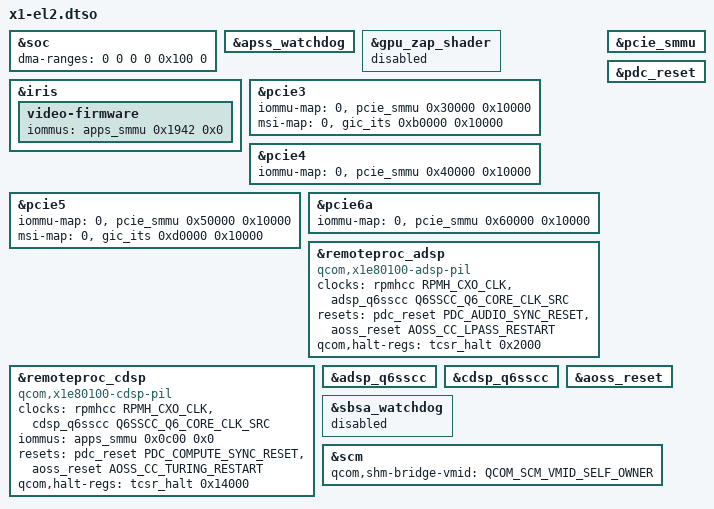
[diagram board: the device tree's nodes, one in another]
// SPDX-License-Identifier: BSD-3-Clause
#include <dt-bindings/clock/qcom,rpmh.h>
#include <dt-bindings/clock/qcom,x1e80100-q6sscc.h>
#include <dt-bindings/firmware/qcom,scm.h>
#include <dt-bindings/reset/qcom,sdm845-aoss.h>
#include <dt-bindings/reset/qcom,sdm845-pdc.h>

/*
 * x1 specific modifications required to boot in EL2.
 */

/dts-v1/;
/plugin/;



&soc {
	#address-cells = <2>;
	#size-cells = <2>;
	dma-ranges = <0 0 0 0 0x100 0>;
	ranges = <0 0 0 0 0x100 0>;
};

&apss_watchdog {
	status = "okay";
};

/* We can't and don't need to use zap shader in EL2 as linux can zap the gpu on it's own. */
&gpu_zap_shader {
	status = "disabled";
};

&iris {
	/* Use generic firmware in EL2 and enable it by default */
//	status = "okay";
//	firmware-name = "qcom/vpu/vpu30_p4.mbn";

	video-firmware {
		iommus = <&apps_smmu 0x1942 0x0>;
	};
};

/*
 * When running under Gunyah, this IOMMU is controlled by the firmware,
 * however when we take ownership of it in EL2, we need to configure
 * it properly to use PCIe.
 *
 * Additionally, it seems like ITS emulation in Gunyah is broken so we
 * can't use MSI on some PCIe controllers in EL1. But we can add them
 * here for EL2.
 */
&pcie3 {
	iommu-map = <0 &pcie_smmu 0x30000 0x10000>;
	msi-map = <0 &gic_its 0xb0000 0x10000>;
};

&pcie4 {
	iommu-map = <0 &pcie_smmu 0x40000 0x10000>;
};

&pcie5 {
	iommu-map = <0 &pcie_smmu 0x50000 0x10000>;
	msi-map = <0 &gic_its 0xd0000 0x10000>;
};

&pcie6a {
	iommu-map = <0 &pcie_smmu 0x60000 0x10000>;
};

&pcie_smmu {
	status = "okay";
};

&remoteproc_adsp {
	/*
	 * Started by qcom_q6v5_adsp without TZ PAS. No iommus: the ADSP streams stay in
	 * bypass as with the hypervisor; a Linux domain with only the carveouts mapped
	 * makes the ADSP fault on its peripheral accesses.
	 */
	compatible = "qcom,x1e80100-adsp-pil";
	clocks = <&rpmhcc RPMH_CXO_CLK>,
		 <&adsp_q6sscc Q6SSCC_Q6_CORE_CLK_SRC>;
	clock-names = "xo", "core";
	resets = <&pdc_reset PDC_AUDIO_SYNC_RESET>,
		 <&aoss_reset AOSS_CC_LPASS_RESTART>;
	reset-names = "pdc_sync", "restart";
	qcom,halt-regs = <&tcsr_halt 0x2000>;
};

&remoteproc_cdsp {
	/* Started by qcom_q6v5_adsp without TZ PAS */
	compatible = "qcom,x1e80100-cdsp-pil";
	clocks = <&rpmhcc RPMH_CXO_CLK>,
		 <&cdsp_q6sscc Q6SSCC_Q6_CORE_CLK_SRC>;
	clock-names = "xo", "core";
	iommus = <&apps_smmu 0x0c00 0x0>;
	resets = <&pdc_reset PDC_COMPUTE_SYNC_RESET>,
		 <&aoss_reset AOSS_CC_TURING_RESTART>;
	reset-names = "pdc_sync", "restart";
	qcom,halt-regs = <&tcsr_halt 0x14000>;
};

&pdc_reset {
	status = "okay";
};

&adsp_q6sscc {
	status = "okay";
};

&cdsp_q6sscc {
	status = "okay";
};

&aoss_reset {
	status = "okay";
};

/*
 * The "SBSA watchdog" is implemented in software in Gunyah
 * and can't be used when running in EL2.
 */
&sbsa_watchdog {
	status = "disabled";
};

&scm {
	qcom,shm-bridge-vmid = <QCOM_SCM_VMID_SELF_OWNER>;
};
